# S32K324_M7 register map
Vendor: NXP Semiconductors; File version: 1.1
CPU: CM7 r0p1, little endian, MPU, FPU, VTOR, 4 interrupt priority bits
Registers are 32-bit, read-write, reset 0x0 unless marked. A register's access mark holds for its fields unless they carry their own. Offsets are from the block's base; [hi:lo] are bit positions; {n}, {i} and the like mark numbered series; 'fields as' and 'values as' point back to an identical list.

## XRDC
Base 0x40278000
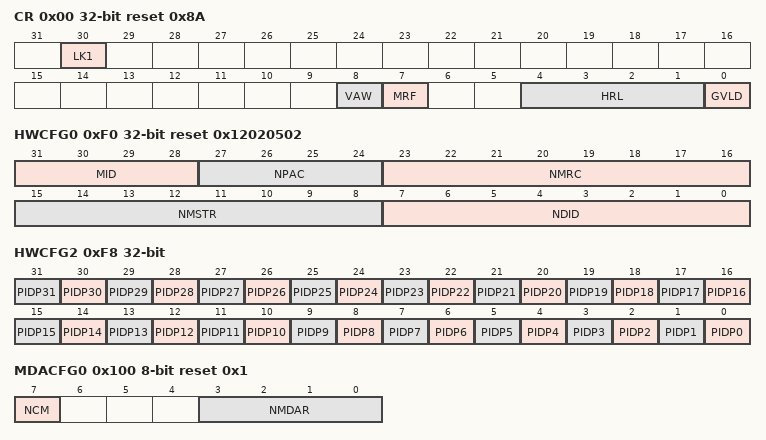
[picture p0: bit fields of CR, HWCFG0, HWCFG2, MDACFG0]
0x00 CR reset 0x8A — Control
  [30] LK1 — Lock
    on read: 0=UNLOCKED_READ; 1=LOCKED (Locks) | on write: 1=LOCKED (Locks)
  [8] VAW ro — Virtualization Aware
    0=NOTVIRTL (Not virtualization-aware); 1=VIRTUAL (Virtualization-aware)
  [7] MRF ro — Memory Region Format
    1=SMPU (SMPU family format)
  [4:1] HRL ro — Hardware Revision Level
  [0] GVLD — Global Valid (XRDC Global Enable/Disable)
    0=DISABLE (Disables); 1=ENABLE (Enables)
0xF0 HWCFG0 ro reset 0x12020502 — Hardware Configuration 0
  [31:28] MID — Module ID
  [27:24] NPAC — Number Of PACs
  [23:16] NMRC — Number of MRCs
  [15:8] NMSTR — Number Of Bus Masters
  [7:0] NDID — Number Of DIDs
0xF4 HWCFG1 ro (reset mask 0xFFFFFFF0) — Hardware Configuration 1
  [3:0] DID — Domain Identifier
0xF8 HWCFG2 ro — Hardware Configuration 2
  [all] fields
    0=NOBMSOURCE (Does not have PID register); 1=BMSOURCE (Has PID register)
  [n] PIDP{n} (n=0..31) — Process Identifier Present
0x100 MDACFG0 8-bit ro reset 0x1 — Master Domain Assignment Configuration
  [7] NCM — Noncore Master
    0=PROC (Core master or master does not exist); 1=NONPROC (Noncore master)
  [3:0] NMDAR — Number Of Master Domain Assignment Registers
    0=ZERO (Master does not exist); {v}=NUMBER (Number of registers) (v=1..8)
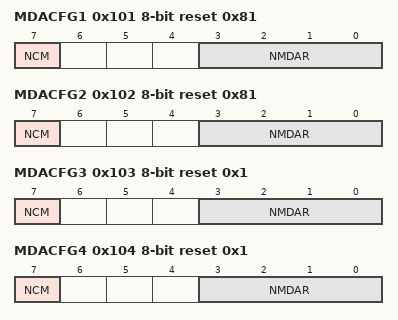
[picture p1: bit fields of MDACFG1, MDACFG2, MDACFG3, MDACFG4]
0x101 MDACFG1 8-bit ro reset 0x81 — Master Domain Assignment Configuration
  fields as MDACFG0
0x102 MDACFG2 8-bit ro reset 0x81 — Master Domain Assignment Configuration
  fields as MDACFG0
0x103 MDACFG3 8-bit ro reset 0x1 — Master Domain Assignment Configuration
  fields as MDACFG0
0x104 MDACFG4 8-bit ro reset 0x1 — Master Domain Assignment Configuration
  fields as MDACFG0
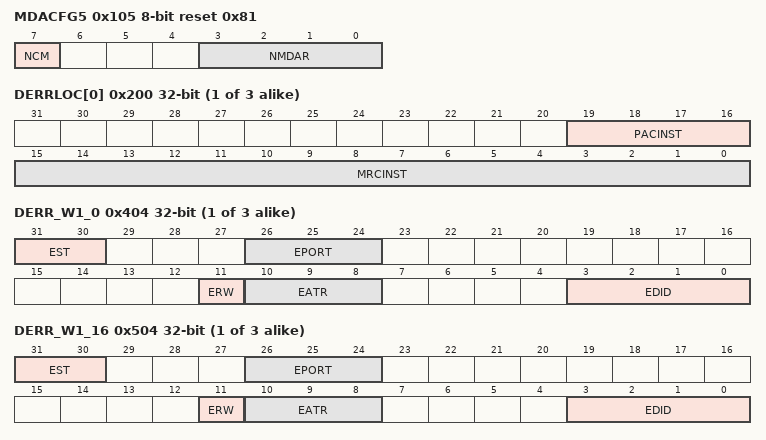
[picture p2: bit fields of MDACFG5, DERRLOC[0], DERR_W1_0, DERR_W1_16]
0x105 MDACFG5 8-bit ro reset 0x81 — Master Domain Assignment Configuration
  fields as MDACFG0
0x140 MRCFG0 8-bit ro reset 0x10 — Memory Region Configuration
  [4:0] NMRGD — Number Of Memory Region Descriptors
    0=ZERO (MRC does not exist); 4=FOUR (4); 8=EIGHT (8); 12=TWELVE (12); 16=SIXTEEN (16)
0x141 MRCFG1 8-bit ro reset 0x10 — Memory Region Configuration
  fields as MRCFG0
0x142 MRCFG2 8-bit ro reset 0x4 — Memory Region Configuration
  fields as MRCFG0
{0x200+4i} DERRLOC[{i}] (i=0..2) ro — Domain Error Location
  [19:16] PACINST — PAC Instance
  [15:0] MRCINST — MRC Instance
{0x400+0x10*i} DERR_W0_{i} ro (i=0..2) — Domain Error Word 0
  [31:0] EADDR — Error Address
{0x404+0x10*i} DERR_W1_{i} ro (i=0..2) — Domain Error Word 1
  [31:30] EST — Error State
    0=NO_VIOLTN (No access violations detected); 1=NO_VIOLTN (No access violations detected); 2=SNGL_VIOLTN (A single access violation has been detected); 3=MULT_VIOLTN (Multiple access violations have been detected)
  [26:24] EPORT — Error Port
  [11] ERW — Error Read Or Write
    0=READ_ACCESS; 1=WRITE_ACCESS
  [10:8] EATR — Error Attributes
    0=SECUSER_INSTR (Secure user mode, instruction fetch access); 1=SECUSER_DATA (Secure user mode, data access); 2=SECPRIV_INSTR (Secure privileged mode, instruction fetch access); 3=SECPRIV_DATA (Secure privileged mode, data access); 4=NONSEC_USER_INSTR (Nonsecure user mode, instruction fetch access); 5=NONSEC_USER_DATA (Nonsecure user mode, data access); 6=NONSEC_PRIV_INSTR (Nonsecure privileged mode, instruction fetch access); 7=NONSEC_PRIV_DATA (Nonsecure privileged mode, data access)
  [3:0] EDID — Error Domain Identifier
{0x40C+0x10*i} DERR_W3_{i} (i=0..2) — Domain Error Word 3
  [31:30] RECR — Rearm Error Capture Registers
    0=NO_EFFECT; 1=REARM (Rearms error capture, resets error capture registers, and deasserts instance bit in DERRLOCd); 2=NO_EFFECT; 3=NO_EFFECT
{0x400+0x10*i} DERR_W0_{i} ro (i=16..18) — Domain Error Word 0
  [31:0] EADDR — Error Address
{0x404+0x10*i} DERR_W1_{i} ro (i=16..18) — Domain Error Word 1
  fields as DERR_W1_0
{0x40C+0x10*i} DERR_W3_{i} (i=16..18) — Domain Error Word 3
  fields as DERR_W3_0
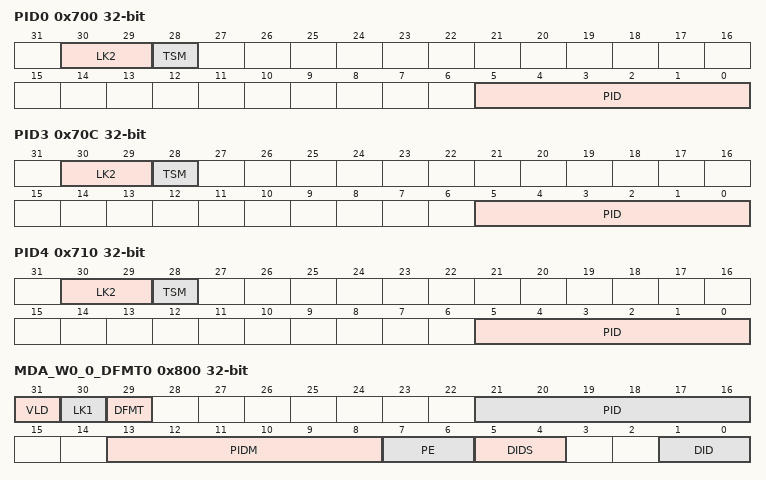
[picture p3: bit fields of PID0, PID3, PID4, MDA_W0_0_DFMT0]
0x700 PID0 — Process Identifier
  [30:29] LK2 — Lock
    0=ANY_SEC_PRIV_WRT (Any secure privileged write); 1=ANY_SEC_PRIV_WRT (Any secure privileged write); 2=BUS_MASTER_ONLY (Secure privileged writes from master only); 3=LOCKED (Locks)
  [28] TSM — Three-State Model
  [5:0] PID — Process Identifier
0x70C PID3 — Process Identifier
  fields as PID0
0x710 PID4 — Process Identifier
  fields as PID0
0x800 MDA_W0_0_DFMT0 — Master Domain Assignment
  [31] VLD — Valid
    0=INVALID; 1=VALID
  [30] LK1 — Lock
    values as CR.LK1
  [29] DFMT ro — Domain Format
    0=PROC (Core bus master domain assignment (DFMT0))
  [21:16] PID — Process Identifier
  [13:8] PIDM — Process Identifier Mask
  [7:6] PE — Process Identifier Enable
    0=NOPROCID (No PID is included); 1=NOPROCID (No PID is included); 2=Partial domain hit = (PID & ~PIDM) == (PIDm[PID] & ~PIDM); 3=Partial domain hit = ~((PID & ~PIDM) == (PIDm[PID] & ~PIDM))
  [5:4] DIDS — DID Select
    0=USE_REG_DID (Use the DID field of this register); 1=USE_INPUT_DID (Use the input DID); 2=USE_CONCAT (Concatenate bits 3-2 of this register with the least significant 2 bits of the input DID (DID_in[1:0]))
  [1:0] DID — Domain Identifier
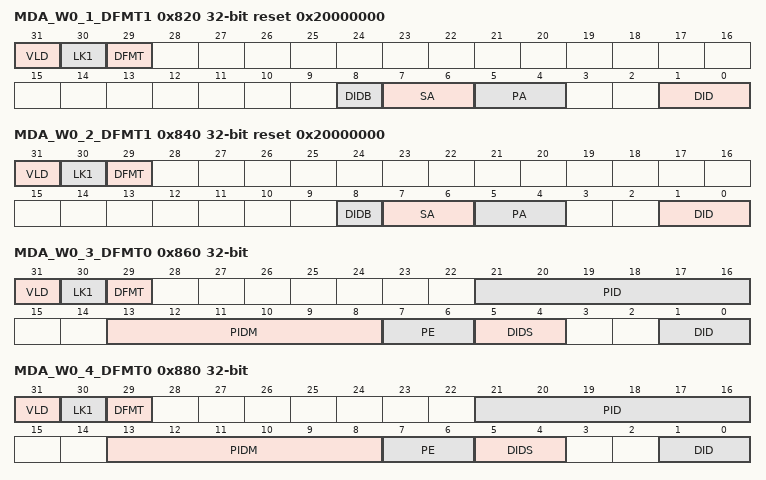
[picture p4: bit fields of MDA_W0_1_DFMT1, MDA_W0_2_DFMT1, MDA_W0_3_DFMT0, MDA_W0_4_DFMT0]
0x820 MDA_W0_1_DFMT1 reset 0x20000000 — Master Domain Assignment
  [31] VLD — Valid
    0=INVALID; 1=VALID
  [30] LK1 — Lock
    values as CR.LK1
  [29] DFMT ro — Domain Format
    1=NONPROC (Bus master domain assignment (DFMT1))
  [8] DIDB — DID Bypass
    0=MDAN30 (Bypass DID input); 1=DID (Use DID input)
  [7:6] SA — Secure Attribute
    0=SECURE (Force to secure); 1=NONSECURE (Force to nonsecure); 0b1x=USE_ATTR_DIRCTLY (Use secure attribute from the master)
  [5:4] PA — Privileged Attribute
    0=FORCE2USER (Force to user); 1=FORCE2PRIV (Force to privileged); 0b1x=USE_BMSTR_ATTR (Use privileged attribute from the master)
  [1:0] DID — Domain Identifier
0x840 MDA_W0_2_DFMT1 reset 0x20000000 — Master Domain Assignment
  fields as MDA_W0_1_DFMT1
0x860 MDA_W0_3_DFMT0 — Master Domain Assignment
  fields as MDA_W0_0_DFMT0
0x880 MDA_W0_4_DFMT0 — Master Domain Assignment
  fields as MDA_W0_0_DFMT0
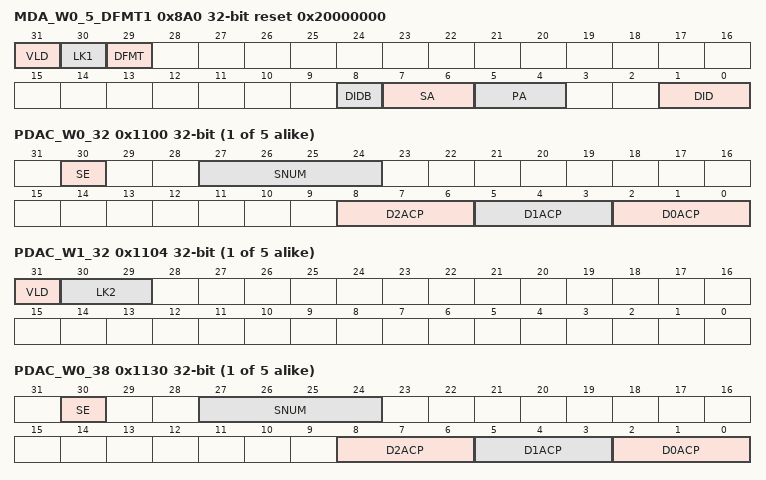
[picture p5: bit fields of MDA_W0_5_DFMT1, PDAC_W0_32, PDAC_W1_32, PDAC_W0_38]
0x8A0 MDA_W0_5_DFMT1 reset 0x20000000 — Master Domain Assignment
  fields as MDA_W0_1_DFMT1
{0x1000+8i} PDAC_W0_{i} (i=32..36) — Peripheral Domain Access Control Word 0
  [30] SE — Semaphore Enable
    0=DISABLE (Disables); 1=ENABLE (Enables)
  [27:24] SNUM — Semaphore Number
  [8:6] D2ACP — Domain Access Control Policy
  [5:3] D1ACP — Domain Access Control Policy
  [2:0] D0ACP — Domain Access Control Policy
{0x1004+8i} PDAC_W1_{i} (i=32..36) — Peripheral Domain Access Control Word 1
  [31] VLD — Valid
    0=INVALID; 1=VALID
  [30:29] LK2 — Lock
    0=ENTIRE (Both words can be written to); 1=ENTIRE (Both words can be written to); 2=DXACP (Domain d can update only its associated DdACP field-all other fields are read-only); 3=LOCKED (Locks (both words are read-only))
{0x1000+8i} PDAC_W0_{i} (i=38..42) — Peripheral Domain Access Control Word 0
  fields as PDAC_W0_32
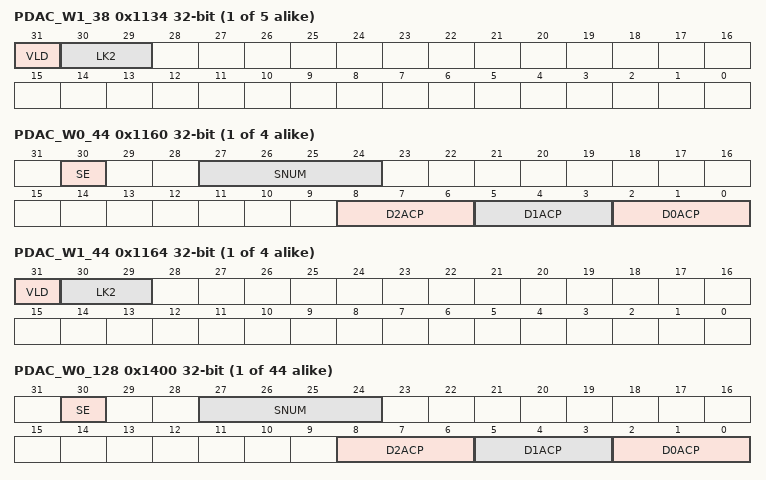
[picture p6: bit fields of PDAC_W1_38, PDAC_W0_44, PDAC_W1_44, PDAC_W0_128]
{0x1004+8i} PDAC_W1_{i} (i=38..42) — Peripheral Domain Access Control Word 1
  fields as PDAC_W1_32
{0x1000+8i} PDAC_W0_{i} (i=44..47) — Peripheral Domain Access Control Word 0
  fields as PDAC_W0_32
{0x1004+8i} PDAC_W1_{i} (i=44..47) — Peripheral Domain Access Control Word 1
  fields as PDAC_W1_32
{0x1000+8i} PDAC_W0_{i} (i=128..171) — Peripheral Domain Access Control Word 0
  fields as PDAC_W0_32
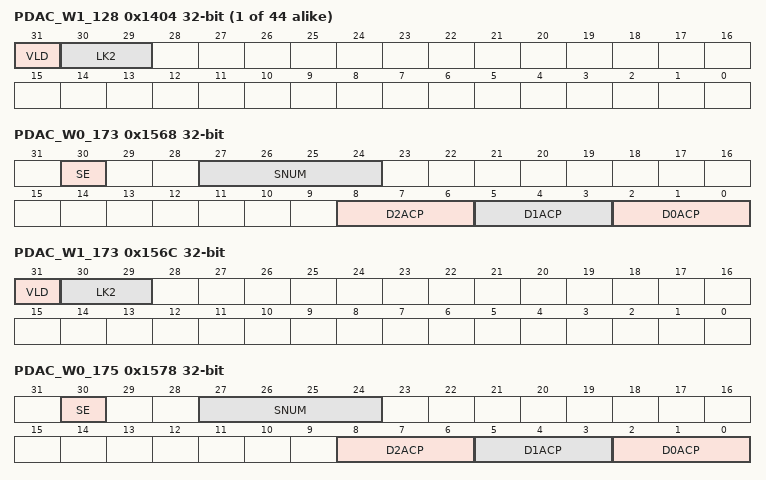
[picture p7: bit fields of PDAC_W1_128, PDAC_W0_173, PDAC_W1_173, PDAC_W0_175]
{0x1004+8i} PDAC_W1_{i} (i=128..171) — Peripheral Domain Access Control Word 1
  fields as PDAC_W1_32
0x1568 PDAC_W0_173 — Peripheral Domain Access Control Word 0
  fields as PDAC_W0_32
0x156C PDAC_W1_173 — Peripheral Domain Access Control Word 1
  fields as PDAC_W1_32
0x1578 PDAC_W0_175 — Peripheral Domain Access Control Word 0
  fields as PDAC_W0_32
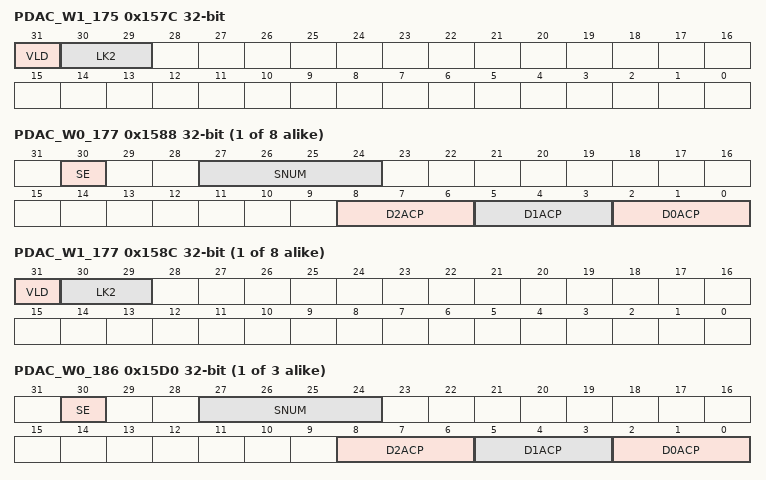
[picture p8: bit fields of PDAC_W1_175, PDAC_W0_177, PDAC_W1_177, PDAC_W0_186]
0x157C PDAC_W1_175 — Peripheral Domain Access Control Word 1
  fields as PDAC_W1_32
{0x1000+8i} PDAC_W0_{i} (i=177..184) — Peripheral Domain Access Control Word 0
  fields as PDAC_W0_32
{0x1004+8i} PDAC_W1_{i} (i=177..184) — Peripheral Domain Access Control Word 1
  fields as PDAC_W1_32
{0x1000+8i} PDAC_W0_{i} (i=186..188) — Peripheral Domain Access Control Word 0
  fields as PDAC_W0_32
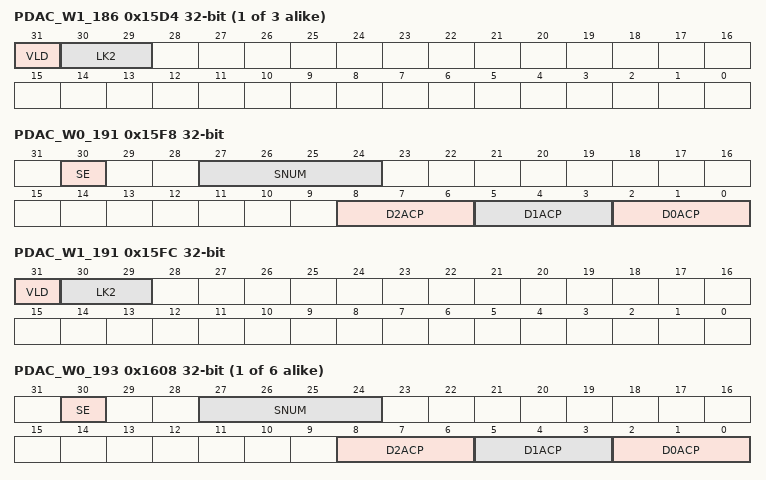
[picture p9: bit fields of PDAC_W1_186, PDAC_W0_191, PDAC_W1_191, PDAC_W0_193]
{0x1004+8i} PDAC_W1_{i} (i=186..188) — Peripheral Domain Access Control Word 1
  fields as PDAC_W1_32
0x15F8 PDAC_W0_191 — Peripheral Domain Access Control Word 0
  fields as PDAC_W0_32
0x15FC PDAC_W1_191 — Peripheral Domain Access Control Word 1
  fields as PDAC_W1_32
{0x1000+8i} PDAC_W0_{i} (i=193..198) — Peripheral Domain Access Control Word 0
  fields as PDAC_W0_32
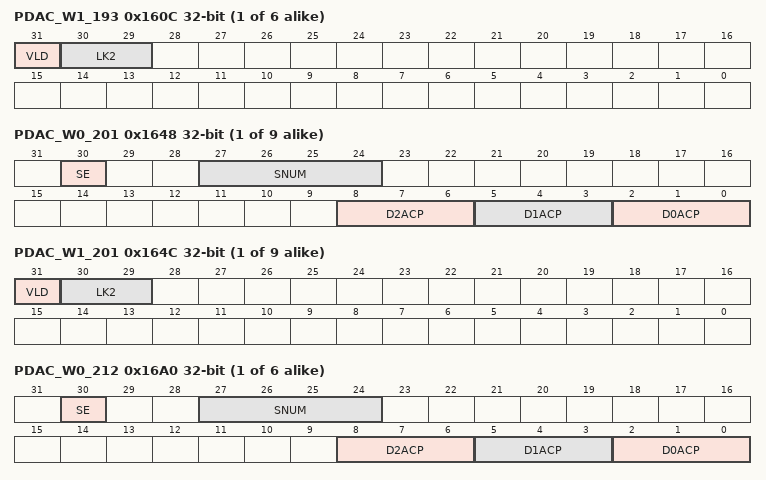
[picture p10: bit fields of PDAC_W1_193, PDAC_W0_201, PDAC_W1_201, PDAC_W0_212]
{0x1004+8i} PDAC_W1_{i} (i=193..198) — Peripheral Domain Access Control Word 1
  fields as PDAC_W1_32
{0x1000+8i} PDAC_W0_{i} (i=201..209) — Peripheral Domain Access Control Word 0
  fields as PDAC_W0_32
{0x1004+8i} PDAC_W1_{i} (i=201..209) — Peripheral Domain Access Control Word 1
  fields as PDAC_W1_32
{0x1000+8i} PDAC_W0_{i} (i=212..217) — Peripheral Domain Access Control Word 0
  fields as PDAC_W0_32
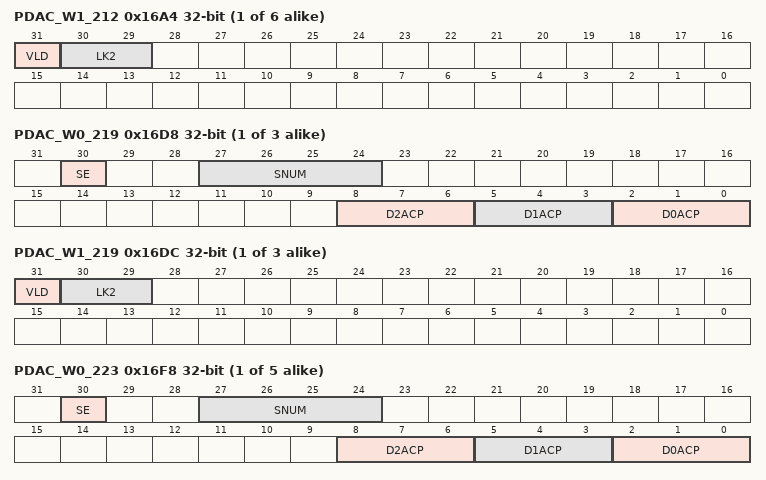
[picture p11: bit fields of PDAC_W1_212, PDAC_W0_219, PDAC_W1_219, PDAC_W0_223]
{0x1004+8i} PDAC_W1_{i} (i=212..217) — Peripheral Domain Access Control Word 1
  fields as PDAC_W1_32
{0x1000+8i} PDAC_W0_{i} (i=219..221) — Peripheral Domain Access Control Word 0
  fields as PDAC_W0_32
{0x1004+8i} PDAC_W1_{i} (i=219..221) — Peripheral Domain Access Control Word 1
  fields as PDAC_W1_32
{0x1000+8i} PDAC_W0_{i} (i=223..227) — Peripheral Domain Access Control Word 0
  fields as PDAC_W0_32
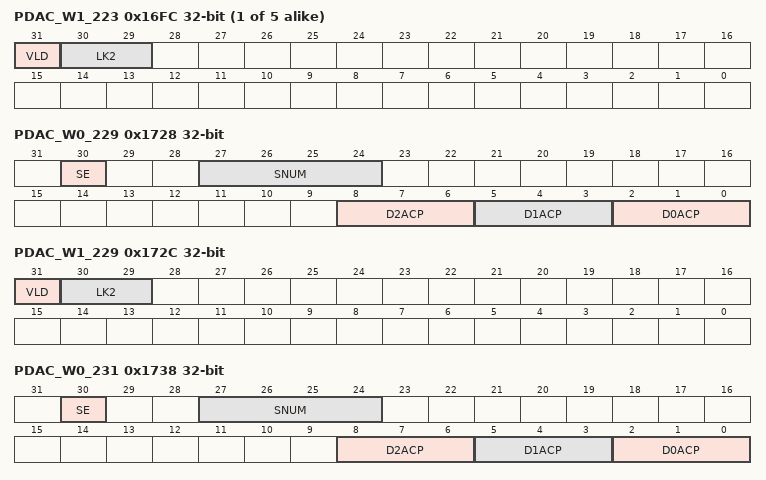
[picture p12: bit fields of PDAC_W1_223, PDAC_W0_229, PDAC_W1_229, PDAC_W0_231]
{0x1004+8i} PDAC_W1_{i} (i=223..227) — Peripheral Domain Access Control Word 1
  fields as PDAC_W1_32
0x1728 PDAC_W0_229 — Peripheral Domain Access Control Word 0
  fields as PDAC_W0_32
0x172C PDAC_W1_229 — Peripheral Domain Access Control Word 1
  fields as PDAC_W1_32
0x1738 PDAC_W0_231 — Peripheral Domain Access Control Word 0
  fields as PDAC_W0_32
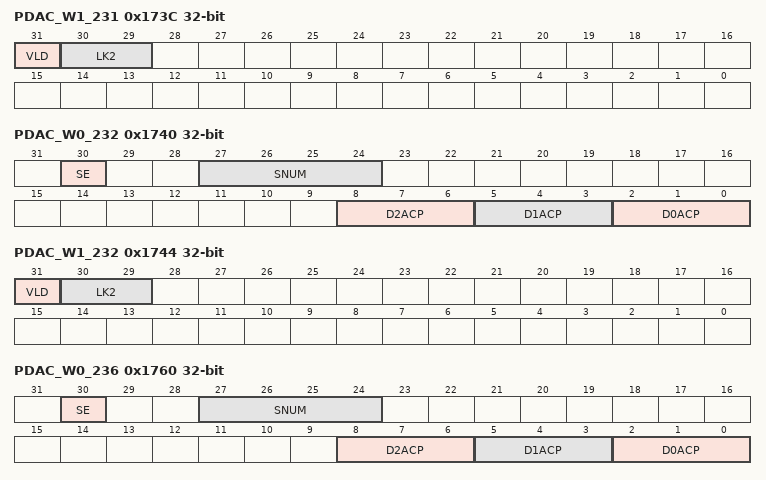
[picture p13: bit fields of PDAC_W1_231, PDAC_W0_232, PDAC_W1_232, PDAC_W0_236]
0x173C PDAC_W1_231 — Peripheral Domain Access Control Word 1
  fields as PDAC_W1_32
0x1740 PDAC_W0_232 — Peripheral Domain Access Control Word 0
  fields as PDAC_W0_32
0x1744 PDAC_W1_232 — Peripheral Domain Access Control Word 1
  fields as PDAC_W1_32
0x1760 PDAC_W0_236 — Peripheral Domain Access Control Word 0
  fields as PDAC_W0_32
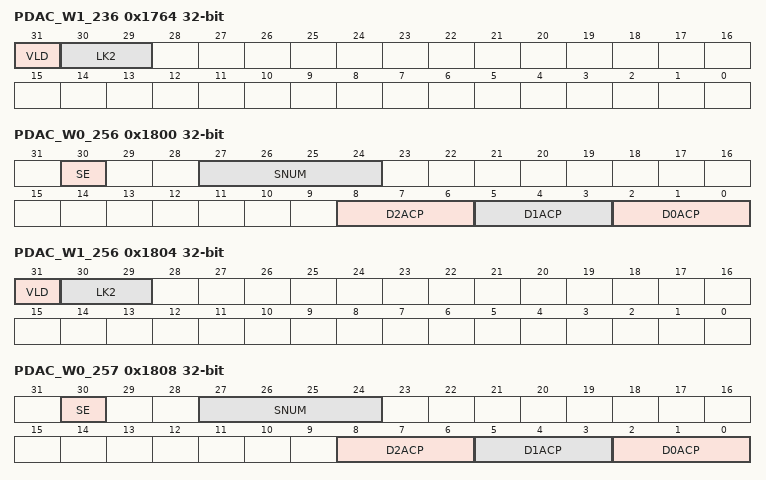
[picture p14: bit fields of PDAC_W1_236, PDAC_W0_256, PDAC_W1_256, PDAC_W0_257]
0x1764 PDAC_W1_236 — Peripheral Domain Access Control Word 1
  fields as PDAC_W1_32
0x1800 PDAC_W0_256 — Peripheral Domain Access Control Word 0
  fields as PDAC_W0_32
0x1804 PDAC_W1_256 — Peripheral Domain Access Control Word 1
  fields as PDAC_W1_32
0x1808 PDAC_W0_257 — Peripheral Domain Access Control Word 0
  fields as PDAC_W0_32
0x180C PDAC_W1_257 — Peripheral Domain Access Control Word 1
  fields as PDAC_W1_32
{0x1000+8i} PDAC_W0_{i} (i=260..281) — Peripheral Domain Access Control Word 0
  fields as PDAC_W0_32
{0x1004+8i} PDAC_W1_{i} (i=260..281) — Peripheral Domain Access Control Word 1
  fields as PDAC_W1_32
0x18D8 PDAC_W0_283 — Peripheral Domain Access Control Word 0
  fields as PDAC_W0_32
0x18DC PDAC_W1_283 — Peripheral Domain Access Control Word 1
  fields as PDAC_W1_32
0x18E8 PDAC_W0_285 — Peripheral Domain Access Control Word 0
  fields as PDAC_W0_32
0x18EC PDAC_W1_285 — Peripheral Domain Access Control Word 1
  fields as PDAC_W1_32
0x1900 PDAC_W0_288 — Peripheral Domain Access Control Word 0
  fields as PDAC_W0_32
0x1904 PDAC_W1_288 — Peripheral Domain Access Control Word 1
  fields as PDAC_W1_32
{0x1000+8i} PDAC_W0_{i} (i=291..298) — Peripheral Domain Access Control Word 0
  fields as PDAC_W0_32
{0x1004+8i} PDAC_W1_{i} (i=291..298) — Peripheral Domain Access Control Word 1
  fields as PDAC_W1_32
0x1978 PDAC_W0_303 — Peripheral Domain Access Control Word 0
  fields as PDAC_W0_32
0x197C PDAC_W1_303 — Peripheral Domain Access Control Word 1
  fields as PDAC_W1_32
0x1980 PDAC_W0_304 — Peripheral Domain Access Control Word 0
  fields as PDAC_W0_32
0x1984 PDAC_W1_304 — Peripheral Domain Access Control Word 1
  fields as PDAC_W1_32
0x1998 PDAC_W0_307 — Peripheral Domain Access Control Word 0
  fields as PDAC_W0_32
0x199C PDAC_W1_307 — Peripheral Domain Access Control Word 1
  fields as PDAC_W1_32
0x19B8 PDAC_W0_311 — Peripheral Domain Access Control Word 0
  fields as PDAC_W0_32
0x19BC PDAC_W1_311 — Peripheral Domain Access Control Word 1
  fields as PDAC_W1_32
0x19D0 PDAC_W0_314 — Peripheral Domain Access Control Word 0
  fields as PDAC_W0_32
0x19D4 PDAC_W1_314 — Peripheral Domain Access Control Word 1
  fields as PDAC_W1_32
0x19D8 PDAC_W0_315 — Peripheral Domain Access Control Word 0
  fields as PDAC_W0_32
0x19DC PDAC_W1_315 — Peripheral Domain Access Control Word 1
  fields as PDAC_W1_32
{0x2000+0x20*i} MRGD_W0_{i} reset 0x1 (i=0..35) — Memory Region Descriptor Word 0
  [31:5] SRTADDR — Start Address
{0x2004+0x20*i} MRGD_W1_{i} reset 0x1F (i=0..35) — Memory Region Descriptor Word 1
  [31:5] ENDADDR — End Address
{0x2008+0x20*i} MRGD_W2_{i} (i=0..35) — Memory Region Descriptor Word 2
  [30] SE — Semaphore Enable
    0=EXCLUDE (Disables); 1=INCLUDE (Enables)
  [27:24] SNUM — Semaphore Number
  [8:6] D2ACP — Domain Access Control Policy
  [5:3] D1ACP — Domain Access Control Policy
  [2:0] D0ACP — Domain Access Control Policy
{0x200C+0x20*i} MRGD_W3_{i} (i=0..35) — Memory Region Descriptor Word 3
  [31] VLD — Valid
    0=INVALID; 1=VALID
  [30:29] LK2 — Lock
    0=ENTIRE (All words in the set can be written to); 2=ONLYX (Domain d can update only its associated DdACP field; all other fields are read-only); 3=LOCKED (Locks (all words are read-only))
